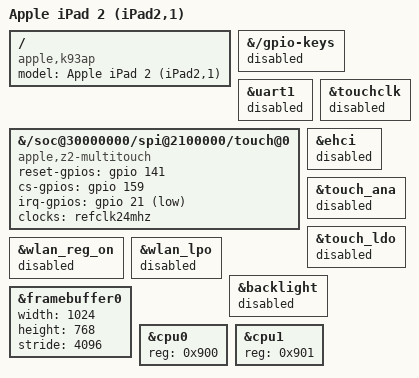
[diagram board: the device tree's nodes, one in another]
/*
 * iPad 2 Wi-Fi (iPad2,1 / K93AP / S5L8940X), on top of the iPad mini 1 tree.
 *
 * The two boards share the SoC block map: AIC, GPIO, PMGR, UART0, SPI1, I2C0,
 * CLCD, SGX, the PL310 and the FMI sit at the same addresses in both ADTs
 * (iOS 8.4.1 / 12H321).  What differs is the board around it: K93 has no PWM
 * block at 0x3500000, its Wi-Fi is a BCM4329 on SDIO rather than a BCM4334
 * on HSIC, and the PMU switch map has not been checked.  Everything that is
 * not known to match is switched off until it is ported.
 */
/include/ "p105ap.dts"

/ {
	compatible = "apple,k93ap", "apple,s5l8940x", "apple,arm";
	model = "Apple iPad 2 (iPad2,1)";
};

/* Button pins not checked against the K93 ADT yet. */
&{/gpio-keys} { status = "disabled"; };

/* BCM4334 Bluetooth on UART1: K93 has no UART1 in its ADT. */
&uart1 { status = "disabled"; };

/*
 * Z2 touch.  The K93 ADT /arm-io/spi1/multi-touch ("multi-touch,k94") gives
 * GPIOs as (port << 8) | pin, eight to a port: function-reset 0x1105 is pin
 * 141, function-enable_cs 0x1307 is pin 159, and the interrupt is GPIO 21
 * (P105: 21, 103 and 22).  Its 32 kHz is PMU GPIO0 (function-clock_enable),
 * which iBoot already leaves at 0x11 -- there is no PWM block on K93 -- so
 * the driver is handed the fixed reference only to have a clock at all.
 * function-power_ldo is 0x0200 (LDO index 0); no supply is wired here until
 * that LDO is mapped, and z2-boot -M switches candidates by hand.
 */
&touchclk { status = "disabled"; };
&{/soc@30000000/spi@2100000/touch@0} {
	compatible = "apple,z2-multitouch";
	/delete-property/ hv-supply;
	/delete-property/ core-supply;
	reset-gpios = <&gpio 141 0>;
	cs-gpios = <&gpio 159 0>;
	irq-gpios = <&gpio 21 1>;
	clocks = <&refclk24mhz>;
};

/* The P105 Wi-Fi hangs off EHCI over HSIC; the K93 one is on SDIO. */
&ehci { status = "disabled"; };

/* PMU switches and the WLED are the P105 map; leave the iBoot state alone. */
&touch_ana { status = "disabled"; };
&touch_ldo { status = "disabled"; };
&wlan_reg_on { status = "disabled"; };
&wlan_lpo { status = "disabled"; };
&backlight { status = "disabled"; };

/*
 * iBoot leaves the K93 CLCD scanning out at the same base as P105, but the
 * panel is driven landscape: the live CLCD reads 0x3a104044 = 0x9f6fc000,
 * 0x3a104048 = 0x1000 (a 4096-byte line, 1024 pixels of 32 bits) and a
 * window of 0x0400 x 0x0300.  So 1024 wide, 768 high -- 768 lines of 4096,
 * 3 MiB, inside fb_region.  Declared 768x1024 the way P105 is, the console
 * came out sheared and then filled only the left three quarters.
 */
&framebuffer0 {
	width = <1024>;
	height = <768>;
	stride = <4096>;
};

/*
 * K93's A5 reports MPIDR 0x900 for the boot core (dmesg: "Booting Linux on
 * physical CPU 0x900"); P105's are 0xa00/0xa01.  With the P105 numbers the
 * boot CPU matched no node, the kernel fell back to its default map and
 * capped the system at one core.
 */
&cpu0 { reg = <0x900>; };
&cpu1 { reg = <0x901>; };
